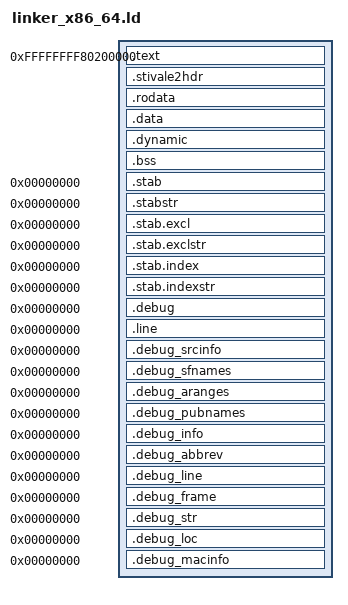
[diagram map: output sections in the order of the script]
ENTRY(kernel_init)

PHDRS
{
    null    PT_NULL    FLAGS(0) ;                   /* Null segment */
    text    PT_LOAD    FLAGS((1 << 0) | (1 << 2)) ; /* Execute + Read */
    rodata  PT_LOAD    FLAGS((1 << 2)) ;            /* Read only */
    data    PT_LOAD    FLAGS((1 << 1) | (1 << 2)) ; /* Write + Read */
    dynamic PT_DYNAMIC FLAGS((1 << 1) | (1 << 2)) ; /* Dynamic segment needed for PIE */
}

SECTIONS
{
    /* We wanna be placed in the higher half, 2MiB above 0 in physical memory. */
    . = 0xffffffff80200000;
    
    /* Then let's place all the other traditional executable sections afterwards. */
    .text : ALIGN(0x1000) {
        *(.text*)
    } :text

    /* We place the .stivalehdr section containing the header in its own section, */
    /* and we use the KEEP directive on it to make sure it doesn't get discarded. */
    .stivale2hdr : ALIGN(0x1000) {
        KEEP(*(.stivale2hdr))
    } :rodata

    .rodata : ALIGN(0x1000) {
        *(.rodata*)
        KEEP(*(SORT(.ctors)))
        KEEP(*(.ctors))
    } :rodata

    .data : ALIGN(0x1000) {
        *(.data*)
    } :data

    .dynamic : ALIGN(0x1000) {
        *(.dynamic)
    } :data :dynamic


    .bss : ALIGN(0x1000) {
        *(COMMON)
        *(.bss*)
    } :data

	/* Stabs debugging sections. */
    .stab          0 : { *(.stab) }
    .stabstr       0 : { *(.stabstr) }
    .stab.excl     0 : { *(.stab.excl) }
    .stab.exclstr  0 : { *(.stab.exclstr) }
    .stab.index    0 : { *(.stab.index) }
    .stab.indexstr 0 : { *(.stab.indexstr) }

    /* DWARF debug sections.
       Symbols in the DWARF debugging sections are relative to the beginning
       of the section so we begin them at 0. */

    /* DWARF 1 */
    .debug          0 : { *(.debug) }
    .line           0 : { *(.line) }

    /* GNU DWARF 1 extensions */
    .debug_srcinfo  0 : { *(.debug_srcinfo) }
    .debug_sfnames  0 : { *(.debug_sfnames) }

    /* DWARF 1.1 and DWARF 2 */
    .debug_aranges  0 : { *(.debug_aranges) }
    .debug_pubnames 0 : { *(.debug_pubnames) }

    /* DWARF 2 */
    .debug_info     0 : { *(.debug_info) }
    .debug_abbrev   0 : { *(.debug_abbrev) }
    .debug_line     0 : { *(.debug_line) }
    .debug_frame    0 : { *(.debug_frame) }
    .debug_str      0 : { *(.debug_str) }
    .debug_loc      0 : { *(.debug_loc) }
    .debug_macinfo  0 : { *(.debug_macinfo) }
}
